# ESP32 register map
Vendor: ESPRESSIF SYSTEMS (SHANGHAI) CO., LTD.; Series: ESP32 Series; File version: 17
CPU: Xtensa LX6 r0p0, little endian, no MPU, FPU, 0 interrupt priority bits
Address unit: 32 bits
Registers are 32-bit, read-write, reset 0x0 unless marked. A register's access mark holds for its fields unless they carry their own. Offsets are from the block's base; [hi:lo] are bit positions; {n}, {i} and the like mark numbered series.

## BTDM — Dual mode Bluetooth Core peripheral
Base 0x3FF71000
0x00 BTCNTL — BR/EDR control register
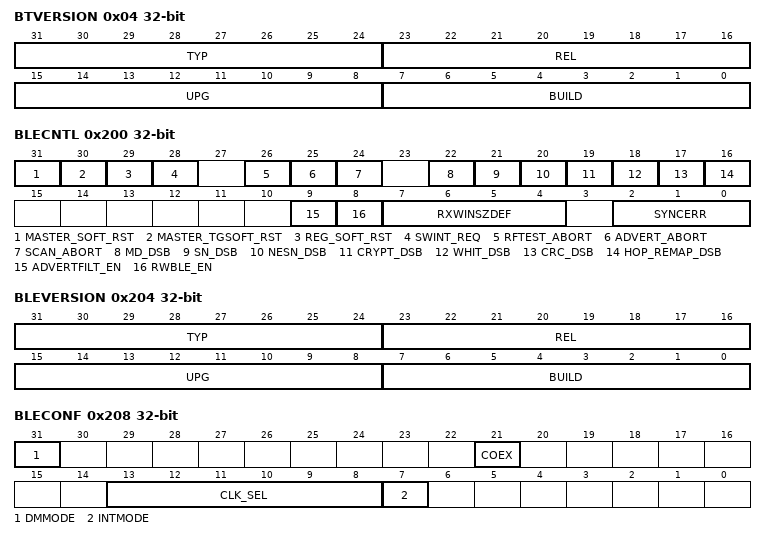
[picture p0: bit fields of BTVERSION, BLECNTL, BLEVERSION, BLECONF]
0x04 BTVERSION access not given — BR/EDR peripheral version
  [31:24] TYP — BR/EDR Core Type (This corresponds to Bluetooth Assigned Numbers document, Core specification versions section)
  [23:16] REL — BR/EDR Core version Major release number
  [15:8] UPG — BR/EDR Core Upgrade number
  [7:0] BUILD — BR/EDR Core Build number
0x0C BTINTCNTL — BR/EDR interrupt control register
0x10 BTINTSTAT access not given — BR/EDR interrupt status register
0x14 BTINTRAWSTAT access not given — BR/EDR interrupt raw status register
0x18 BTINTACK access not given — BR/EDR interrupt acknowledgement register
0x100 PMU_CTRL — Power Management Unit control register
0x200 BLECNTL — BLE control register
  [31] MASTER_SOFT_RST — Reset the complete BLE Core except registers and timing generator (Master state machine reset)
  [30] MASTER_TGSOFT_RST — Master timing generator reset
  [29] REG_SOFT_RST — Reset of the complete register block
  [28] SWINT_REQ — Force a software interrupt
  [26] RFTEST_ABORT — Abort the current RF test
  [25] ADVERT_ABORT — Abort the current advertising event
  [24] SCAN_ABORT — Abort the current scan window
  [22] MD_DSB — More data bit disable (0=Normal operation, 1=Allow a one Tx/Rx exchange whatever the MD bits are)
  [21] SN_DSB — Sequence number disable
  [20] NESN_DSB — Acknowledge scheme disable
  [19] CRYPT_DSB — Encryption and decryption disable
  [18] WHIT_DSB — Whitening disable
  [17] CRC_DSB — If enabled, CRC is removed from stream, when disabled, CRC is appended for user check
  [16] HOP_REMAP_DSB — Hop remapping algorithm disable
  [9] ADVERTFILT_EN — Filter to only correctly received packets
  [8] RWBLE_EN — RW-BLE Core Exchange table pre-fetch mechanism enable
  [7:4] RXWINSZDEF — Default RX window size in μs
  [2:0] SYNCERR — Max number of bit errors allowed to recognize a syncword
0x204 BLEVERSION access not given — BLE peripheral version
  [31:24] TYP — BLE Core Type (This corresponds to Bluetooth Assigned Numbers document, Core specification versions section)
  [23:16] REL — BLE Core version Major release number
  [15:8] UPG — BLE Core Upgrade number
  [7:0] BUILD — BLE Core Build number
0x208 BLECONF access not given — RW BLE hardware configuration register
  [31] DMMODE — Bluetooth baseband core dual mode
  [21] COEX — RF coexistence mechanism
  [13:8] CLK_SEL — Operating frequency (in MHz)
  [7] INTMODE — Interruption Mode (0: Pulse, 1: Level)
0x208 BLECONF access not given — BLE configuration register
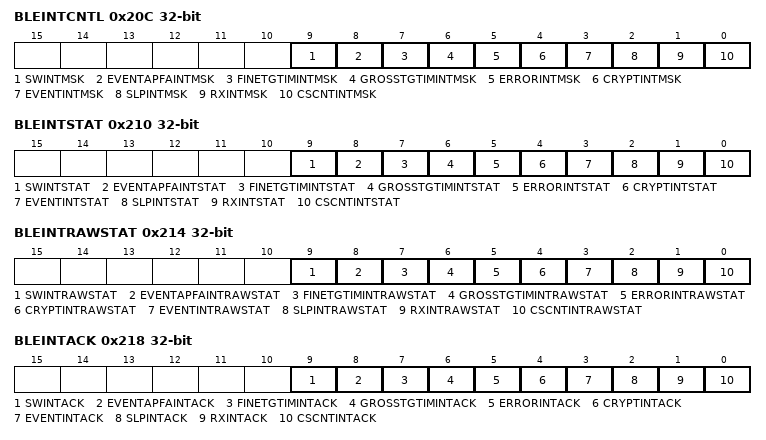
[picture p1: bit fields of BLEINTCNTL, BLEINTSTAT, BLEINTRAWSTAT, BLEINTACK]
0x20C BLEINTCNTL — BLE interrupt controller register
  [9] SWINTMSK — Software triggered interrupt mask
  [8] EVENTAPFAINTMSK — End of event/anticipated pre-fetch abort interrupt mask
  [7] FINETGTIMINTMSK — Fine target timer interrupt mask
  [6] GROSSTGTIMINTMSK — Gross target timer interrupt mask
  [5] ERRORINTMSK — Error interrupt mask
  [4] CRYPTINTMSK — Encryption engine interrupt mask
  [3] EVENTINTMSK — End of event (adv, scan, conn) interrupt mask
  [2] SLPINTMSK — Sleep mode interrupt mask
  [1] RXINTMSK — RX interrupt mask
  [0] CSCNTINTMSK — 625μs base time (for active modes) interrupt mask
0x210 BLEINTSTAT access not given — BLE interrupt status register
  [9] SWINTSTAT — Masked software triggered interrupt status
  [8] EVENTAPFAINTSTAT — Masked end of event/anticipated pre-fetch abort interrupt status
  [7] FINETGTIMINTSTAT — Masked fine target timer interrupt status
  [6] GROSSTGTIMINTSTAT — Masked gross target timer interrupt status
  [5] ERRORINTSTAT — Masked error interrupt status
  [4] CRYPTINTSTAT — Masked encryption engine interrupt status
  [3] EVENTINTSTAT — Masked end of event interrupt status
  [2] SLPINTSTAT — Masked sleep mode interrupt status
  [1] RXINTSTAT — Masked packet RX interrupt status
  [0] CSCNTINTSTAT — Masked 625μs base time reference interrupt status
0x214 BLEINTRAWSTAT access not given — BLE interrupt raw status register
  [9] SWINTRAWSTAT — Software triggered interrupt raw status
  [8] EVENTAPFAINTRAWSTAT — End of event/anticipated pre-fetch abort interrupt raw status
  [7] FINETGTIMINTRAWSTAT — Fine target timer interrupt raw status
  [6] GROSSTGTIMINTRAWSTAT — Gross target timer interrupt raw status
  [5] ERRORINTRAWSTAT — Error interrupt raw status
  [4] CRYPTINTRAWSTAT — Encryption engine interrupt raw status
  [3] EVENTINTRAWSTAT — End of event interrupt raw status
  [2] SLPINTRAWSTAT — Sleep mode interrupt raw status
  [1] RXINTRAWSTAT — Packet RX interrupt raw status
  [0] CSCNTINTRAWSTAT — 625μs base time reference interrupt raw status
0x218 BLEINTACK access not given — BLE interrupt acknowledgement register
  [9] SWINTACK — Software triggered interrupt acknowledgment bit
  [8] EVENTAPFAINTACK — End of event/anticipated pre-fetch abort interrupt acknowledgment bit
  [7] FINETGTIMINTACK — Fine target timer interrupt acknowledgment bit
  [6] GROSSTGTIMINTACK — Gross target timer interrupt acknowledgment bit
  [5] ERRORINTACK — Error interrupt acknowledgment bit
  [4] CRYPTINTACK — Encryption engine interrupt acknowledgment bit
  [3] EVENTINTACK — End of event interrupt acknowledgment bit
  [2] SLPINTACK — Sleep mode interrupt acknowledgment bit
  [1] RXINTACK — Packet RX interrupt acknowledgment bit
  [0] CSCNTINTACK — 625μs base time reference interrupt acknowledgment bit
0x21C BLEBASETIMECNT access not given — RW BLE base timer configuration register
  [26:0] BASETIMECNT — Current value of the 625us slot counter
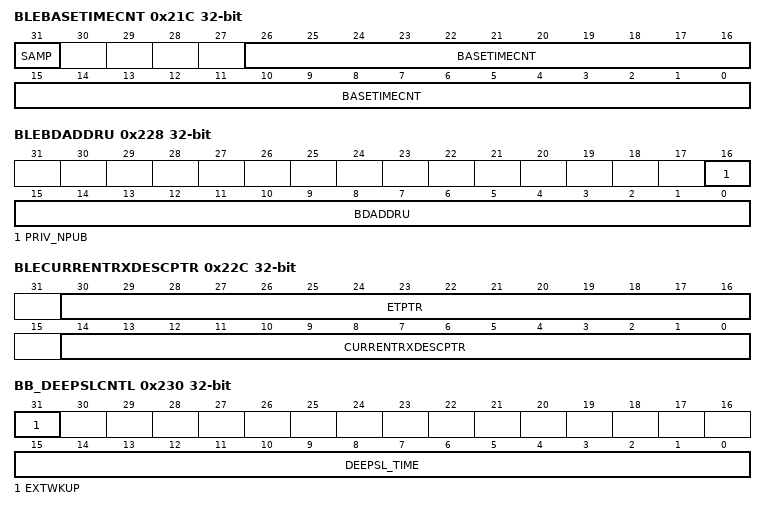
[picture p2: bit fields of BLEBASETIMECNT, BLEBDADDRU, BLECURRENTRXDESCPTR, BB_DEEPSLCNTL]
0x21C BLEBASETIMECNT — Base time reference counter
  [31] SAMP — Sample the base time counter
  [26:0] BASETIMECNT — Base time counter value
0x220 BLEFINETIMECNT — Fine time reference counter
  [9:0] FINECNT — Fine time counter value
0x224 BLEBDADDRL — BLE device address LSB register
  [31:0] BDADDRL
0x228 BLEBDADDRU — BLE device address MSB register
  [16] PRIV_NPUB — Address privacy indicator (0=public, 1=private)
  [15:0] BDADDRU
0x22C BLECURRENTRXDESCPTR — BLE RX descriptor pointer for the receive buffer chained list
  [30:16] ETPTR — Pointer that determines the starting point of the Exchange Table
  [14:0] CURRENTRXDESCPTR — Pointer that determines the starting point of the RX Buffer Chained List
0x230 BB_DEEPSLCNTL — Deep sleep control register
  [31] EXTWKUP — External wake-up enable
  [15:0] DEEPSL_TIME — Duration of the sleep in 312.5us units
0x238 BB_DEEPSLSTAT access not given — Deep sleep status register
  [15] DEEPSL_STAT — Deep sleep status (1: In sleep/pending, 0: Awake)
0x240 BB_FINECNTCORR — Fine timer correction register
0x244 BB_BASETIMECNTCORR — Base timer correction register
0x250 BLEDIAGCNTL — Diagnostics control register
0x254 BLEDIAGSTAT access not given — Diagnostics status register
0x260 BLEERRORTYPESTAT — Error type status register
0x270 BLERADIOCNTL0 — Radio interface control register 0
0x274 BLERADIOCNTL1 — Radio interface control register 1
0x280 BLERADIOPWRUPDN — RX/TX power up/down phase register
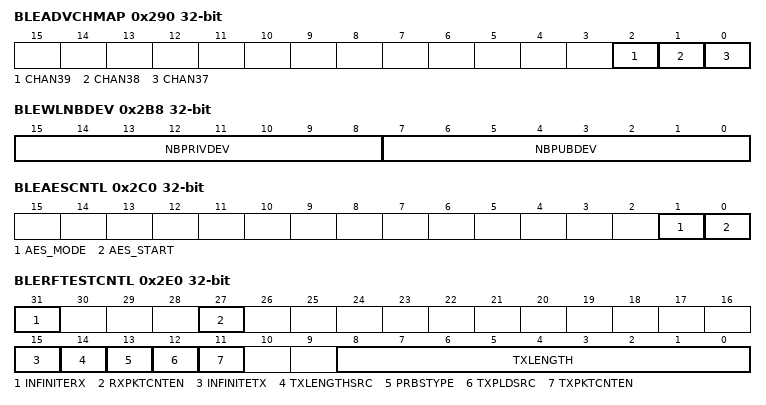
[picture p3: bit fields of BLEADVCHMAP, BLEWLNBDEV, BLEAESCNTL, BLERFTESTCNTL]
0x290 BLEADVCHMAP — Advertising Channel Map
  [2] CHAN39 — Use channel 39 to send advertisements
  [1] CHAN38 — Use channel 38 to send advertisements
  [0] CHAN37 — Use channel 37 to send advertisements
0x2A0 BLEADVTIM — Advertising Packet Interval
  [13:0] ADVINT — Time in us between sent advertisement packets
0x2B0 BLEWLPUBADDRPTR — Pointer to public devices whitelist
0x2B4 BLEWLPRIVADDRPTR — Pointer to private devices whitelist
0x2B8 BLEWLNBDEV — Number of devices in whitelist
  [15:8] NBPRIVDEV — Number of private devices in the white list
  [7:0] NBPUBDEV — Number of public devices in the white list
0x2C0 BLEAESCNTL — AES encryption control register
  [1] AES_MODE — AES mode (0=encrypt, 1=decrypt)
  [0] AES_START — Start AES encryption/decryption
{0x2C4+4i} BLEAESKEY{i} (i=0..3) — AES key[{32i+31}:{32i}]
0x2D4 BLEAESPTR — Pointer to the block to encrypt/decrypt with AES
0x2E0 BLERFTESTCNTL — Test Mode control register
  [31] INFINITERX — Infinite RX window
  [27] RXPKTCNTEN — Enable RX packet count
  [15] INFINITETX — Infinite TX packet
  [14] TXLENGTHSRC — TX packet payload length source (0=TXADVLEN, 1=BLERFTESTCNTL.TXLENGTH)
  [13] PRBSTYPE — PRBS payload type (0=PRBS9, 1=PRBS15)
  [12] TXPLDSRC — TX packet payload source (0=Control Structure, 1=PRBS)
  [11] TXPKTCNTEN — Enable TX packet count
  [8:0] TXLENGTH — TX packet length in number of bytes
0x2E4 BLERFTESTTXSTAT access not given — Number of valid packets transmited during Test
0x2E8 BLERFTESTRXSTAT access not given — Number of valid packets received during Test
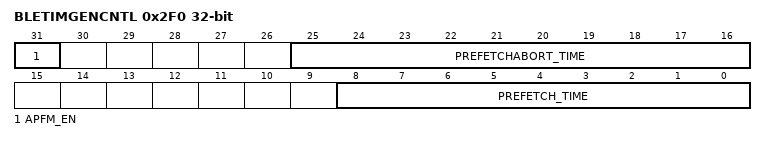
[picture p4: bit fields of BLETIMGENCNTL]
0x2F0 BLETIMGENCNTL — Pre-Fecth mechanism control
  [31] APFM_EN — Enable Anticipated Pre-Fetch Abort mechanism
  [25:16] PREFETCHABORT_TIME — Pre-Fetch abort instant (us)
  [8:0] PREFETCH_TIME — Exchange Table prefetch instant (us)
0x300 BLECOEXIFCNTL0 — Interface Coexistance Control
0x320 BLERALPTR — Resolve Address List pointer
  [15:0] RALPTR — Pointer to Resolve Address List
0x324 BLERALNBDEV — Number of devices in Resolve Address List
  [7:0] NBRALDEV
